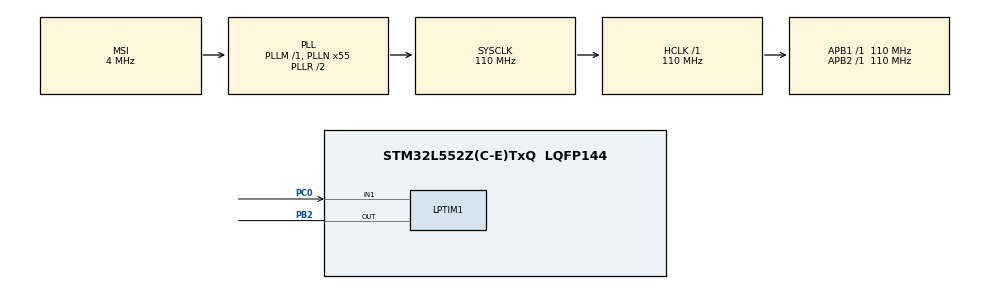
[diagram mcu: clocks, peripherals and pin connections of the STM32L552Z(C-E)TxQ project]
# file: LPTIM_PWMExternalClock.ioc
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Mcu.Family=STM32L5
Mcu.Name=STM32L552Z(C-E)TxQ
Mcu.Package=LQFP144
NVIC.PriorityGroup=NVIC_PRIORITYGROUP_3
PB2.GPIO_Speed=GPIO_SPEED_FREQ_MEDIUM
PB2.Mode=WaveformGeneration
PB2.Signal=LPTIM1_OUT
PC0.GPIO_Speed=GPIO_SPEED_FREQ_MEDIUM
PC0.Mode=Counts_external_clock_standalone_1X_occur1
PC0.Signal=LPTIM1_IN1
ProjectManager.HeapSize=0x200
ProjectManager.StackSize=0x400
ProjectManager.TargetToolchain=EWARM V8.32
RCC.AHBFreq_Value=110000000
RCC.APB1Freq_Value=110000000
RCC.APB1TimFreq_Value=110000000
RCC.APB2Freq_Value=110000000
RCC.APB2TimFreq_Value=110000000
RCC.CortexFreq_Value=110000000
RCC.HCLKFreq_Value=110000000
RCC.HSE_VALUE=16000000
RCC.HSI48_VALUE=48000000
RCC.HSI_VALUE=16000000
RCC.LSE_VALUE=32768
RCC.MSI_VALUE=4000000
RCC.PLLN=55
RCC.SYSCLKFreq_VALUE=110000000
RCC.SYSCLKSource=RCC_SYSCLKSOURCE_PLLCLK
RCC.VCOOutputFreq_Value=220000000
VP_ICACHE_VS_ICACHE.Mode=DirectMappedCache
VP_PWR_VS_DBSignals.Mode=DisableDeadBatterySignals
board=custom

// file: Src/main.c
/* USER CODE BEGIN Header */
/**
  ******************************************************************************
  * @file           : main.c
  * @brief          : Main program body
  ******************************************************************************
  * @attention
  *
  * Copyright (c) 2019 STMicroelectronics.
  * All rights reserved.
  *
  * This software is licensed under terms that can be found in the LICENSE file
  * in the root directory of this software component.
  * If no LICENSE file comes with this software, it is provided AS-IS.
  *
  ******************************************************************************
  */
/* USER CODE END Header */
#include "main.h"

/* USER CODE BEGIN PD */
/* Set the Maximum value of the counter (Auto-Reload) that defines the Period */
#define PeriodValue             (uint32_t) (100 -1)

/* Set the Compare value that defines the duty cycle */
#define PulseValue              (uint32_t) (50 -1)
/* USER CODE END PD */

LPTIM_HandleTypeDef hlptim1;

void SystemClock_Config(void);
static void MX_GPIO_Init(void);
static void MX_ICACHE_Init(void);
static void MX_LPTIM1_Init(void);

int main(void)
{

  /* MCU Configuration--------------------------------------------------------*/

  /* Reset of all peripherals, Initializes the Flash interface and the Systick. */
  HAL_Init();

  /* USER CODE BEGIN Init */
  /* Configure LED_RED */
  BSP_LED_Init(LED_RED);
  /* USER CODE END Init */

  /* Configure the system clock */
  SystemClock_Config();

  /* Initialize all configured peripherals */
  MX_GPIO_Init();
  MX_ICACHE_Init();
  MX_LPTIM1_Init();
  /* USER CODE BEGIN 2 */

  /* BUTTON_WAKEUP (External line 13) will be used to wakeup the system from Stop 2 mode */
  if (BSP_PB_Init(BUTTON_WAKEUP, BUTTON_MODE_EXTI) != BSP_ERROR_NONE)
  {
    Error_Handler();
  }

  /* Start generating the PWM signal */
  /*
   * Period = 99
   * Pulse  = 49
   * According to this configuration, the duty cycle will be equal to 50% and
   * the output frequency will be equal to the input frequency divided by 100
   * since the LPTIM have to count 100 external clock edges each period.
   */
  if (HAL_LPTIM_PWM_Start(&hlptim1, PeriodValue, PulseValue) != HAL_OK)
  {
    Error_Handler();
  }

  /* Enter in Stop mode */
  HAL_PWREx_EnterSTOP1Mode(PWR_STOPENTRY_WFI);

  /* Stop counting when leaving Stop mode */
  if (HAL_LPTIM_PWM_Stop(&hlptim1) != HAL_OK)
  {
    Error_Handler();
  }
  /* USER CODE END 2 */

  /* Infinite loop */
  while (1)
  {

  }
}

void SystemClock_Config(void)
{
  RCC_OscInitTypeDef RCC_OscInitStruct = {0};
  RCC_ClkInitTypeDef RCC_ClkInitStruct = {0};

  /** Configure the main internal regulator output voltage
  */
  if (HAL_PWREx_ControlVoltageScaling(PWR_REGULATOR_VOLTAGE_SCALE0) != HAL_OK)
  {
    Error_Handler();
  }

  /** Initializes the RCC Oscillators according to the specified parameters
  * in the RCC_OscInitTypeDef structure.
  */
  RCC_OscInitStruct.OscillatorType = RCC_OSCILLATORTYPE_MSI;
  RCC_OscInitStruct.MSIState = RCC_MSI_ON;
  RCC_OscInitStruct.MSICalibrationValue = RCC_MSICALIBRATION_DEFAULT;
  RCC_OscInitStruct.MSIClockRange = RCC_MSIRANGE_6;
  RCC_OscInitStruct.PLL.PLLState = RCC_PLL_ON;
  RCC_OscInitStruct.PLL.PLLSource = RCC_PLLSOURCE_MSI;
  RCC_OscInitStruct.PLL.PLLM = 1;
  RCC_OscInitStruct.PLL.PLLN = 55;
  RCC_OscInitStruct.PLL.PLLP = RCC_PLLP_DIV7;
  RCC_OscInitStruct.PLL.PLLQ = RCC_PLLQ_DIV2;
  RCC_OscInitStruct.PLL.PLLR = RCC_PLLR_DIV2;
  if (HAL_RCC_OscConfig(&RCC_OscInitStruct) != HAL_OK)
  {
    Error_Handler();
  }

  /** Initializes the CPU, AHB and APB buses clocks
  */
  RCC_ClkInitStruct.ClockType = RCC_CLOCKTYPE_HCLK|RCC_CLOCKTYPE_SYSCLK
                              |RCC_CLOCKTYPE_PCLK1|RCC_CLOCKTYPE_PCLK2;
  RCC_ClkInitStruct.SYSCLKSource = RCC_SYSCLKSOURCE_PLLCLK;
  RCC_ClkInitStruct.AHBCLKDivider = RCC_SYSCLK_DIV1;
  RCC_ClkInitStruct.APB1CLKDivider = RCC_HCLK_DIV1;
  RCC_ClkInitStruct.APB2CLKDivider = RCC_HCLK_DIV1;

  if (HAL_RCC_ClockConfig(&RCC_ClkInitStruct, FLASH_LATENCY_5) != HAL_OK)
  {
    Error_Handler();
  }
}

static void MX_ICACHE_Init(void)
{

  /** Enable instruction cache in 1-way (direct mapped cache)
  */
  if (HAL_ICACHE_ConfigAssociativityMode(ICACHE_1WAY) != HAL_OK)
  {
    Error_Handler();
  }
  if (HAL_ICACHE_Enable() != HAL_OK)
  {
    Error_Handler();
  }

}

static void MX_LPTIM1_Init(void)
{

  hlptim1.Instance = LPTIM1;
  hlptim1.Init.Clock.Source = LPTIM_CLOCKSOURCE_ULPTIM;
  hlptim1.Init.Clock.Prescaler = LPTIM_PRESCALER_DIV1;
  hlptim1.Init.UltraLowPowerClock.Polarity = LPTIM_CLOCKPOLARITY_RISING;
  hlptim1.Init.UltraLowPowerClock.SampleTime = LPTIM_CLOCKSAMPLETIME_DIRECTTRANSITION;
  hlptim1.Init.Trigger.Source = LPTIM_TRIGSOURCE_SOFTWARE;
  hlptim1.Init.OutputPolarity = LPTIM_OUTPUTPOLARITY_HIGH;
  hlptim1.Init.UpdateMode = LPTIM_UPDATE_IMMEDIATE;
  hlptim1.Init.CounterSource = LPTIM_COUNTERSOURCE_EXTERNAL;
  hlptim1.Init.Input1Source = LPTIM_INPUT1SOURCE_GPIO;
  hlptim1.Init.Input2Source = LPTIM_INPUT2SOURCE_GPIO;
  hlptim1.Init.RepetitionCounter = 0;
  if (HAL_LPTIM_Init(&hlptim1) != HAL_OK)
  {
    Error_Handler();
  }

}

static void MX_GPIO_Init(void)
{

  /* GPIO Ports Clock Enable */
  __HAL_RCC_GPIOC_CLK_ENABLE();
  __HAL_RCC_GPIOB_CLK_ENABLE();

}

void Error_Handler(void)
{
  /* USER CODE BEGIN Error_Handler_Debug */
  /* Turn LED_RED on */
  (void) BSP_LED_On(LED_RED);
  while (1)
  {
  }
  /* USER CODE END Error_Handler_Debug */
}

#ifdef  USE_FULL_ASSERT
/**
  * @brief  Reports the name of the source file and the source line number
  *         where the assert_param error has occurred.
  * @param  file: pointer to the source file name
  * @param  line: assert_param error line source number
  * @retval None
  */
void assert_failed(uint8_t *file, uint32_t line)
{
  /* USER CODE BEGIN 6 */
  /* User can add his own implementation to report the file name and line number,
     ex: printf("Wrong parameters value: file %s on line %d\r\n", file, line) */
  /* Infinite loop */
  while (1)
  {}
  /* USER CODE END 6 */
}
#endif /* USE_FULL_ASSERT */
